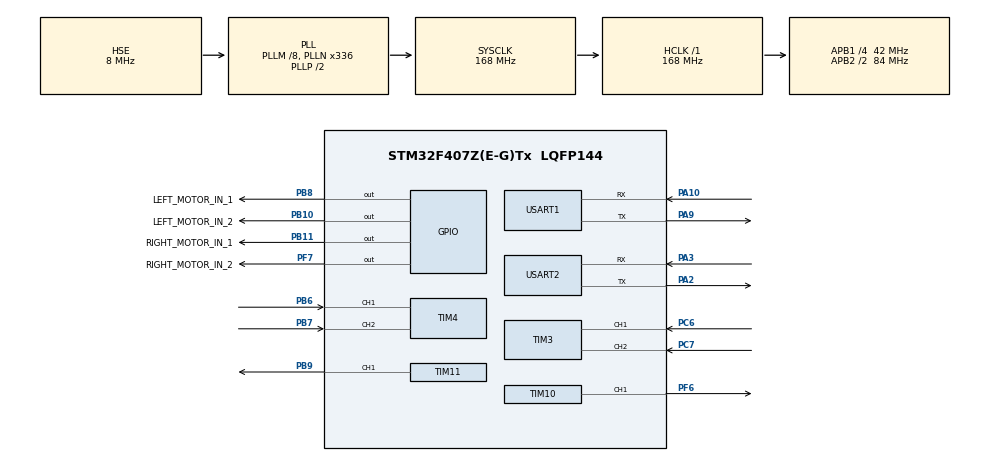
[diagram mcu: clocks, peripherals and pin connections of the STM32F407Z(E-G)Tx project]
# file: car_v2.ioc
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FREERTOS.Tasks01=defaultTask,0,128,StartDefaultTask,Default,NULL,Dynamic,NULL,NULL;encoder_debug,-3,128,start_encoder_debug,As weak,NULL,Dynamic,NULL,NULL
Mcu.Family=STM32F4
Mcu.Name=STM32F407Z(E-G)Tx
Mcu.Package=LQFP144
NVIC.PriorityGroup=NVIC_PRIORITYGROUP_4
NVIC.TIM1_UP_TIM10_IRQn=true\:0\:0\:false\:false\:true\:false\:false\:true
NVIC.TimeBase=TIM1_UP_TIM10_IRQn
NVIC.TimeBaseIP=TIM1
NVIC.USART1_IRQn=true\:5\:0\:false\:false\:true\:true\:true\:true
NVIC.USART2_IRQn=true\:5\:0\:false\:false\:true\:true\:true\:true
PA10.Mode=Asynchronous
PA10.Signal=USART1_RX
PA13.Mode=Serial_Wire
PA13.Signal=SYS_JTMS-SWDIO
PA14.Mode=Serial_Wire
PA14.Signal=SYS_JTCK-SWCLK
PA2.Mode=Asynchronous
PA2.Signal=USART2_TX
PA3.Mode=Asynchronous
PA3.Signal=USART2_RX
PA9.Mode=Asynchronous
PA9.Signal=USART1_TX
PB10.GPIO_Label=LEFT_MOTOR_IN_2
PB10.PinState=GPIO_PIN_SET
PB10.Signal=GPIO_Output
PB11.GPIO_Label=RIGHT_MOTOR_IN_1
PB11.PinState=GPIO_PIN_SET
PB11.Signal=GPIO_Output
PB6.Signal=S_TIM4_CH1
PB7.Signal=S_TIM4_CH2
PB8.GPIO_Label=LEFT_MOTOR_IN_1
PB8.PinState=GPIO_PIN_SET
PB8.Signal=GPIO_Output
PB9.Signal=S_TIM11_CH1
PC6.Signal=S_TIM3_CH1
PC7.Signal=S_TIM3_CH2
PF6.Signal=S_TIM10_CH1
PF7.GPIO_Label=RIGHT_MOTOR_IN_2
PF7.PinState=GPIO_PIN_SET
PF7.Signal=GPIO_Output
PH0-OSC_IN.Mode=HSE-External-Oscillator
PH0-OSC_IN.Signal=RCC_OSC_IN
PH1-OSC_OUT.Mode=HSE-External-Oscillator
PH1-OSC_OUT.Signal=RCC_OSC_OUT
ProjectManager.HeapSize=0x200
ProjectManager.StackSize=0x400
ProjectManager.TargetToolchain=SW4STM32
RCC.48MHZClocksFreq_Value=84000000
RCC.AHBFreq_Value=168000000
RCC.APB1CLKDivider=RCC_HCLK_DIV4
RCC.APB1Freq_Value=42000000
RCC.APB1TimFreq_Value=84000000
RCC.APB2CLKDivider=RCC_HCLK_DIV2
RCC.APB2Freq_Value=84000000
RCC.APB2TimFreq_Value=168000000
RCC.CortexFreq_Value=168000000
RCC.HCLKFreq_Value=168000000
RCC.HSE_VALUE=8000000
RCC.HSI_VALUE=16000000
RCC.LSE_VALUE=32768
RCC.PLLM=8
RCC.PLLN=336
RCC.PLLSourceVirtual=RCC_PLLSOURCE_HSE
RCC.SYSCLKFreq_VALUE=168000000
RCC.SYSCLKSource=RCC_SYSCLKSOURCE_PLLCLK
RCC.VCOOutputFreq_Value=336000000
SH.S_TIM10_CH1.0=TIM10_CH1,PWM Generation1 CH1
SH.S_TIM11_CH1.0=TIM11_CH1,PWM Generation1 CH1
SH.S_TIM3_CH1.0=TIM3_CH1,Encoder_Interface
SH.S_TIM3_CH2.0=TIM3_CH2,Encoder_Interface
SH.S_TIM4_CH1.0=TIM4_CH1,Encoder_Interface
SH.S_TIM4_CH2.0=TIM4_CH2,Encoder_Interface
TIM10.Channel=TIM_CHANNEL_1
TIM11.Channel=TIM_CHANNEL_1
USART1.VirtualMode=VM_ASYNC
USART2.VirtualMode=VM_ASYNC
VP_FREERTOS_VS_CMSIS_V1.Mode=CMSIS_V1
VP_SYS_VS_tim1.Mode=TIM1
VP_TIM10_VS_ClockSourceINT.Mode=Enable_Timer
VP_TIM11_VS_ClockSourceINT.Mode=Enable_Timer
board=custom

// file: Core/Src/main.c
/* USER CODE BEGIN Header */
/**
  ******************************************************************************
  * @file           : main.c
  * @brief          : Main program body
  ******************************************************************************
  * @attention
  *
  * <h2><center>&copy; Copyright (c) 2023 STMicroelectronics.
  * All rights reserved.</center></h2>
  *
  * This software component is licensed by ST under Ultimate Liberty license
  * SLA0044, the "License"; You may not use this file except in compliance with
  * the License. You may obtain a copy of the License at:
  *                             www.st.com/SLA0044
  *
  ******************************************************************************
  */
/* USER CODE END Header */
#include "main.h"
#include "cmsis_os.h"
#include "tim.h"
#include "usart.h"
#include "gpio.h"

/* USER CODE BEGIN Includes */
#include "sensor.h"
#include "usart_safe.h"

/* USER CODE END Includes */

void SystemClock_Config(void);
void MX_FREERTOS_Init(void);

int main(void)
{

  /* MCU Configuration--------------------------------------------------------*/

  /* Reset of all peripherals, Initializes the Flash interface and the Systick. */
  HAL_Init();

  /* Configure the system clock */
  SystemClock_Config();

  /* Initialize all configured peripherals */
  MX_GPIO_Init();
  MX_TIM3_Init();
  MX_TIM4_Init();
  MX_TIM10_Init();
  MX_TIM11_Init();
  MX_USART1_UART_Init();
  MX_USART2_UART_Init();
  /* USER CODE BEGIN 2 */
  HAL_TIM_Encoder_Start(&htim3, TIM_CHANNEL_ALL);
  HAL_TIM_Encoder_Start(&htim4, TIM_CHANNEL_ALL);

  HAL_UART_Receive_IT(&huart2, (uint8_t *)&(self_USART2.temp), 1);
  HAL_UART_Receive_IT(&huart1, (uint8_t *)&(self_USART1.temp), 1);

  print_USARTx(&huart1, "1\n");
  all_sensor_init();
  /* USER CODE END 2 */

  /* Call init function for freertos objects (in freertos.c) */
  MX_FREERTOS_Init();
  /* Start scheduler */
  osKernelStart();

  /* We should never get here as control is now taken by the scheduler */
  /* Infinite loop */
  while (1)
  {

  }
}

void SystemClock_Config(void)
{
  RCC_OscInitTypeDef RCC_OscInitStruct = {0};
  RCC_ClkInitTypeDef RCC_ClkInitStruct = {0};

  /** Configure the main internal regulator output voltage
  */
  __HAL_RCC_PWR_CLK_ENABLE();
  __HAL_PWR_VOLTAGESCALING_CONFIG(PWR_REGULATOR_VOLTAGE_SCALE1);
  /** Initializes the RCC Oscillators according to the specified parameters
  * in the RCC_OscInitTypeDef structure.
  */
  RCC_OscInitStruct.OscillatorType = RCC_OSCILLATORTYPE_HSE;
  RCC_OscInitStruct.HSEState = RCC_HSE_ON;
  RCC_OscInitStruct.PLL.PLLState = RCC_PLL_ON;
  RCC_OscInitStruct.PLL.PLLSource = RCC_PLLSOURCE_HSE;
  RCC_OscInitStruct.PLL.PLLM = 8;
  RCC_OscInitStruct.PLL.PLLN = 336;
  RCC_OscInitStruct.PLL.PLLP = RCC_PLLP_DIV2;
  RCC_OscInitStruct.PLL.PLLQ = 4;
  if (HAL_RCC_OscConfig(&RCC_OscInitStruct) != HAL_OK)
  {
    Error_Handler();
  }
  /** Initializes the CPU, AHB and APB buses clocks
  */
  RCC_ClkInitStruct.ClockType = RCC_CLOCKTYPE_HCLK|RCC_CLOCKTYPE_SYSCLK
                              |RCC_CLOCKTYPE_PCLK1|RCC_CLOCKTYPE_PCLK2;
  RCC_ClkInitStruct.SYSCLKSource = RCC_SYSCLKSOURCE_PLLCLK;
  RCC_ClkInitStruct.AHBCLKDivider = RCC_SYSCLK_DIV1;
  RCC_ClkInitStruct.APB1CLKDivider = RCC_HCLK_DIV4;
  RCC_ClkInitStruct.APB2CLKDivider = RCC_HCLK_DIV2;

  if (HAL_RCC_ClockConfig(&RCC_ClkInitStruct, FLASH_LATENCY_5) != HAL_OK)
  {
    Error_Handler();
  }
}

 /**
  * @brief  Period elapsed callback in non blocking mode
  * @note   This function is called  when TIM1 interrupt took place, inside
  * HAL_TIM_IRQHandler(). It makes a direct call to HAL_IncTick() to increment
  * a global variable "uwTick" used as application time base.
  * @param  htim : TIM handle
  * @retval None
  */
void HAL_TIM_PeriodElapsedCallback(TIM_HandleTypeDef *htim)
{
  if (htim->Instance == TIM1) {
    HAL_IncTick();
  }
}

void Error_Handler(void)
{
  __disable_irq();
  while (1)
  {
  }
}

/************************ (C) COPYRIGHT STMicroelectronics *****END OF FILE****/

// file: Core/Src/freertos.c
/* USER CODE BEGIN Header */
/**
  ******************************************************************************
  * File Name          : freertos.c
  * Description        : Code for freertos applications
  ******************************************************************************
  * @attention
  *
  * <h2><center>&copy; Copyright (c) 2023 STMicroelectronics.
  * All rights reserved.</center></h2>
  *
  * This software component is licensed by ST under Ultimate Liberty license
  * SLA0044, the "License"; You may not use this file except in compliance with
  * the License. You may obtain a copy of the License at:
  *                             www.st.com/SLA0044
  *
  ******************************************************************************
  */
/* USER CODE END Header */

#include "FreeRTOS.h"
#include "task.h"
#include "main.h"
#include "cmsis_os.h"

osThreadId defaultTaskHandle;
osThreadId encoder_debugHandle;

void StartDefaultTask(void const * argument);
void start_encoder_debug(void const * argument);

void MX_FREERTOS_Init(void); /* (MISRA C 2004 rule 8.1) */

/* GetIdleTaskMemory prototype (linked to static allocation support) */
void vApplicationGetIdleTaskMemory( StaticTask_t **ppxIdleTaskTCBBuffer, StackType_t **ppxIdleTaskStackBuffer, uint32_t *pulIdleTaskStackSize );

/* USER CODE BEGIN GET_IDLE_TASK_MEMORY */
static StaticTask_t xIdleTaskTCBBuffer;
static StackType_t xIdleStack[configMINIMAL_STACK_SIZE];

void vApplicationGetIdleTaskMemory( StaticTask_t **ppxIdleTaskTCBBuffer, StackType_t **ppxIdleTaskStackBuffer, uint32_t *pulIdleTaskStackSize )
{
  *ppxIdleTaskTCBBuffer = &xIdleTaskTCBBuffer;
  *ppxIdleTaskStackBuffer = &xIdleStack[0];
  *pulIdleTaskStackSize = configMINIMAL_STACK_SIZE;
  /* place for user code */
}
/* USER CODE END GET_IDLE_TASK_MEMORY */

void MX_FREERTOS_Init(void) {

  /* Create the thread(s) */
  /* definition and creation of defaultTask */
  osThreadDef(defaultTask, StartDefaultTask, osPriorityNormal, 0, 128);
  defaultTaskHandle = osThreadCreate(osThread(defaultTask), NULL);

  /* definition and creation of encoder_debug */
  osThreadDef(encoder_debug, start_encoder_debug, osPriorityIdle, 0, 128);
  encoder_debugHandle = osThreadCreate(osThread(encoder_debug), NULL);

}

void StartDefaultTask(void const * argument)
{
  for(;;)
  {
    osDelay(1);
  }
}

__weak void start_encoder_debug(void const * argument)
{
  for(;;)
  {
    osDelay(1);
  }
}

/************************ (C) COPYRIGHT STMicroelectronics *****END OF FILE****/
